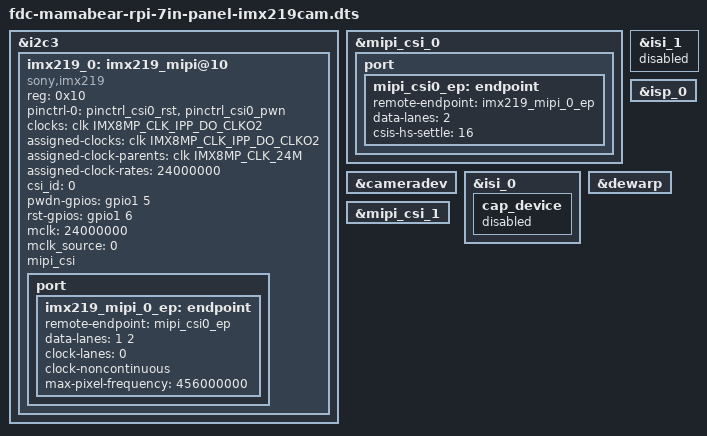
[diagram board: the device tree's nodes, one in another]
// SPDX-License-Identifier: (GPL-2.0+ OR MIT)
/*
 * Copyright 2019-2020 NXP
*/

/dts-v1/;


#include "fdc-mamabear-rpi-7in-panel.dts"

/delete-node/ &ap1302;

&i2c3 {


	imx219_0: imx219_mipi@10 {
		compatible = "sony,imx219";
		reg = <0x10>;
		pinctrl-names = "default";
		pinctrl-0 = <&pinctrl_csi0_rst>, <&pinctrl_csi0_pwn>; 
		clocks = <&clk IMX8MP_CLK_IPP_DO_CLKO2>;
		clock-names = "xclk";
		assigned-clocks = <&clk IMX8MP_CLK_IPP_DO_CLKO2>;
		assigned-clock-parents = <&clk IMX8MP_CLK_24M>;
		assigned-clock-rates = <24000000>;
		csi_id = <0>;
		pwdn-gpios = <&gpio1 5 GPIO_ACTIVE_HIGH>;
		rst-gpios = <&gpio1 6 GPIO_ACTIVE_HIGH>;
	//	reset = <&mipi_cam_reset>;
		mclk = <24000000>;
		mclk_source = <0>;
		
		mipi_csi;
		status = "okay";

		port {
			imx219_mipi_0_ep: endpoint {
				remote-endpoint = <&mipi_csi0_ep>;
				data-lanes = <1 2>;
				clock-lanes = <0>;
				clock-noncontinuous;
				max-pixel-frequency = /bits/ 64 <456000000>;
	
			};
		};
	};


};

&mipi_csi_0 {
	status = "okay";

	port {
		mipi_csi0_ep: endpoint {
			remote-endpoint = <&imx219_mipi_0_ep>;
			data-lanes = <2>;
			csis-hs-settle = <16>;
		};
	};
};

&cameradev {
	status = "okay";
};

&isi_0 {
	cap_device {
		status = "disabled";
	};
};

&isi_1 {
	status = "disabled";

};


&isp_0 {
	status = "okay";
};

&dewarp {
	status = "okay";
};

&mipi_csi_1 {
	/delete-property/ #address-cells;
	/delete-property/ #size-cells;
};
